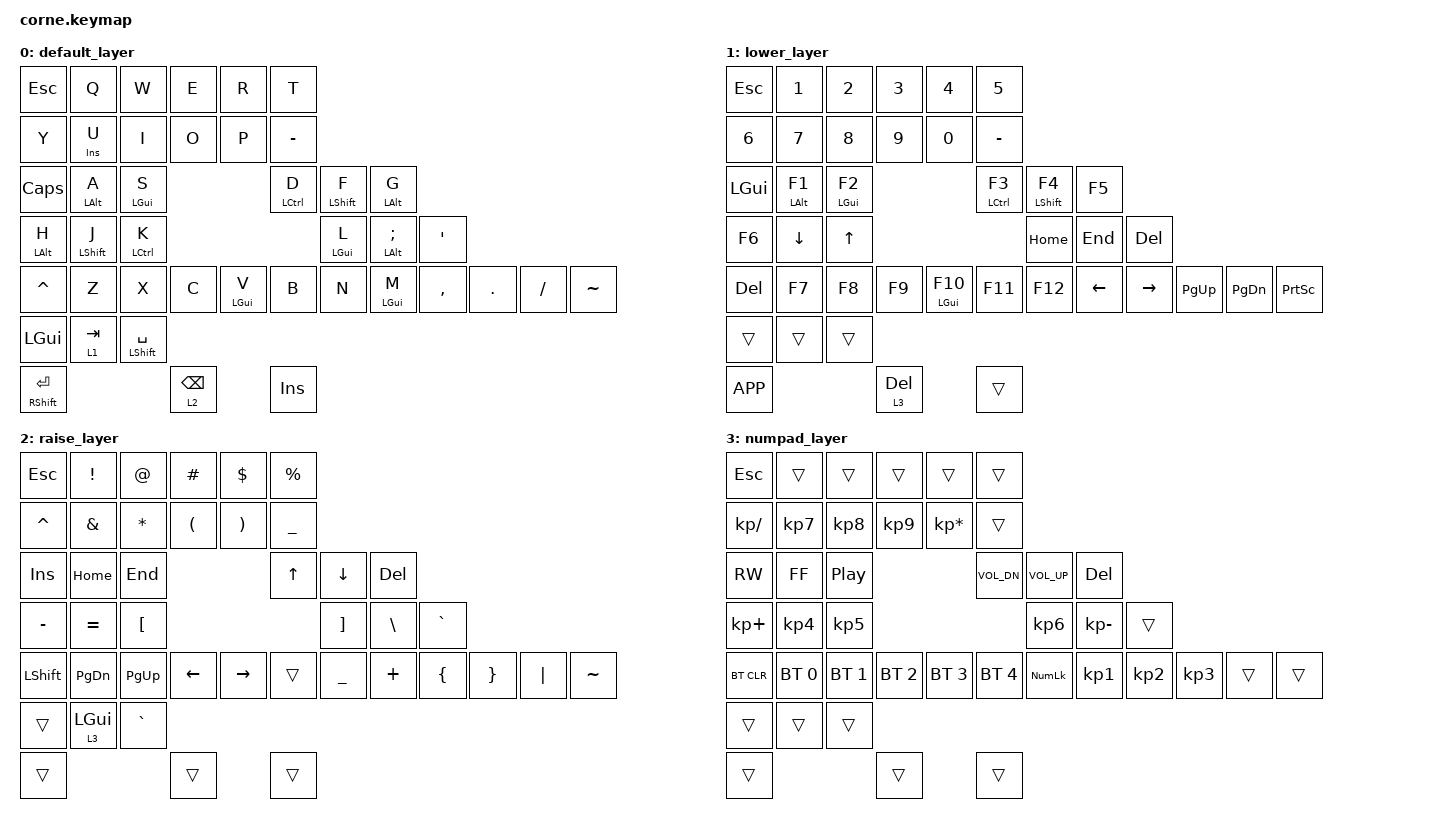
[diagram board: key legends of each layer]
#include <behaviors.dtsi>
#include <dt-bindings/zmk/keys.h>
#include <dt-bindings/zmk/bt.h>

&mt {
    tapping-term-ms = <150>;
    flavor = "tap-preferred";
};
&lt {
    tapping-term-ms = <140>;
    flavor = "tap-preferred";
};

/ {
    behaviors {
        ts: thumb_shifts {
            compatible = "zmk,behavior-hold-tap";
            #binding-cells = <2>;
            flavor = "tap-preferred";
            tapping-term-ms = <150>;
            bindings = <&kp>, <&kp>;
        }; //thumb shift
    }; //behaviors
        
    keymap {
        compatible = "zmk,keymap";
        default_layer {
            bindings = <
                &kp ESC   &kp Q &kp W &kp E &kp R &kp T   
                &kp Y &ts INS U &kp I &kp O &kp P    &kp MINUS
                &kp CLCK &mt LALT A &mt LGUI S &mt LCTRL D &mt LSHFT F &mt LALT G
                &mt LALT H   &mt LSHFT J  &mt LCTRL K     &mt LGUI L &mt LALT SEMI &kp SQT
                &kp CARET &kp Z &kp X &kp C &mt LGUI V &kp B   &kp N &mt LGUI M &kp COMMA &kp DOT &kp FSLH &kp TILDE
                &kp LGUI &lt 1 TAB &ts LEFT_SHIFT SPACE
                &ts RIGHT_SHIFT RET &lt 2 BACKSPACE &kp INS
            >;
        };

        lower_layer {
            bindings = <
                &kp ESC    &kp N1       &kp N2       &kp N3       &kp N4       &kp N5         &kp N6   &kp N7   &kp N8 &kp N9    &kp N0 &kp MINUS
                &kp LGUI &mt LALT                                                             F1 &mt LGUI F2 &mt LCTRL F3 &mt LSHFT F4 &kp F5 &kp F6 &kp DOWN &kp UP &kp HOME &kp END &kp DEL
                &kp DEL &kp F7 &kp F8 &kp F9 &mt LGUI F10 &kp F11 &kp F12   &kp LEFT &kp RIGHT &kp PG_UP -&kp PG_DN &kp PSCRN 
                &trans &trans &trans &kp K_APP &lt 3 DEL &trans
            >;
        }; 
        
        raise_layer {
            bindings = <
                &kp ESC                  &kp EXCL &kp AT &kp HASH &kp DLLR &kp PRCNT   &kp CARET &kp AMPS  &kp ASTRK &kp LPAR &kp RPAR &kp UNDER
                &kp INS &kp HOME &kp END &kp UP &kp DOWN &kp DEL &kp MINUS &kp EQUAL &kp LBKT        &kp RBKT &kp BSLH &kp GRAVE
                &kp LSHFT &kp PG_DN &kp PG_UP&kp LEFT &kp RIGHT &trans
                &kp UNDER &kp PLUS  &kp LBRC        &kp RBRC &kp PIPE &kp TILDE
                &trans &lt 3 LGUI &kp GRAVE &trans &trans &trans
            >;
        };

        numpad_layer {
            bindings = <
&kp ESC &trans &trans &trans &trans &trans            &kp KP_DIVIDE &kp KP_N7 &kp KP_N8 &kp KP_N9 &kp KP_MULTIPLY &trans
&kp C_RW &kp C_FF &kp C_PP &kp C_VOL_DN &kp C_VOL_UP &kp DEL 
&kp KP_PLUS &kp KP_N4 &kp KP_N5 &kp KP_N6 &kp KP_SUBTRACT &trans
&bt BT_CLR &bt BT_SEL 0 &bt BT_SEL 1 &bt BT_SEL 2 &bt BT_SEL 3 &bt BT_SEL 4
&kp KP_NUMLOCK &kp KP_N1 &kp KP_N2 &kp KP_N3 &trans &trans
&trans &trans &trans &trans &trans &trans
            >;
        };

    }; //keymap
}; //end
